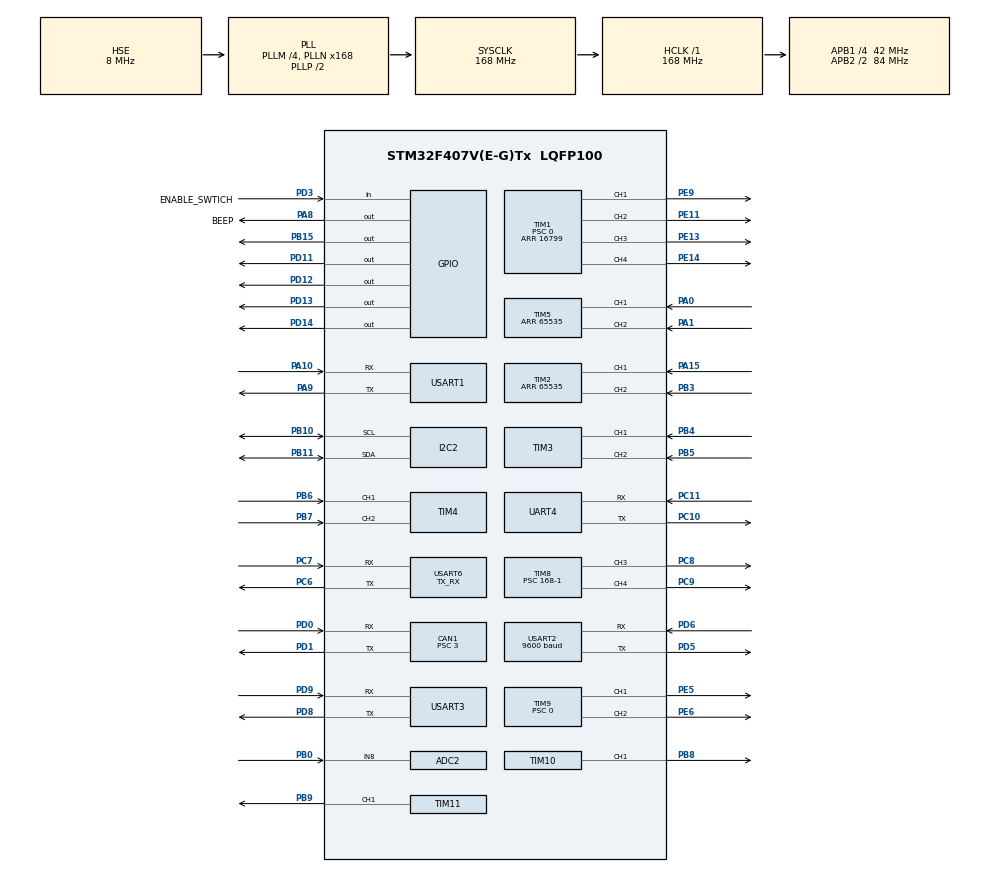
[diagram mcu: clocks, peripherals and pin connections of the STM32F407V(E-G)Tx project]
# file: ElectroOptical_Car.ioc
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ADC2.Channel-0\#ChannelRegularConversion=ADC_CHANNEL_8
ADC2.ContinuousConvMode=ENABLE
ADC2.NbrOfConversionFlag=1
ADC2.Rank-0\#ChannelRegularConversion=1
ADC2.SamplingTime-0\#ChannelRegularConversion=ADC_SAMPLETIME_3CYCLES
ADC2.ScanConvMode=ENABLE
CAN1.ABOM=ENABLE
CAN1.AWUM=ENABLE
CAN1.BS1=CAN_BS1_6TQ
CAN1.BS2=CAN_BS2_7TQ
CAN1.CalculateBaudRate=1000000
CAN1.CalculateTimeBit=1000
CAN1.CalculateTimeQuantum=71.42857142857143
CAN1.Prescaler=3
Dma.ADC2.6.Direction=DMA_PERIPH_TO_MEMORY
Dma.ADC2.6.FIFOMode=DMA_FIFOMODE_DISABLE
Dma.ADC2.6.Instance=DMA2_Stream3
Dma.ADC2.6.MemDataAlignment=DMA_MDATAALIGN_HALFWORD
Dma.ADC2.6.MemInc=DMA_MINC_ENABLE
Dma.ADC2.6.Mode=DMA_CIRCULAR
Dma.ADC2.6.PeriphDataAlignment=DMA_PDATAALIGN_HALFWORD
Dma.ADC2.6.PeriphInc=DMA_PINC_DISABLE
Dma.ADC2.6.Priority=DMA_PRIORITY_LOW
Dma.Request0=USART3_RX
Dma.Request1=USART1_RX
Dma.Request2=USART6_RX
Dma.Request3=USART3_TX
Dma.Request4=UART4_RX
Dma.Request5=UART4_TX
Dma.Request6=ADC2
Dma.UART4_RX.4.Direction=DMA_PERIPH_TO_MEMORY
Dma.UART4_RX.4.FIFOMode=DMA_FIFOMODE_ENABLE
Dma.UART4_RX.4.FIFOThreshold=DMA_FIFO_THRESHOLD_FULL
Dma.UART4_RX.4.Instance=DMA1_Stream2
Dma.UART4_RX.4.MemBurst=DMA_MBURST_SINGLE
Dma.UART4_RX.4.MemDataAlignment=DMA_MDATAALIGN_BYTE
Dma.UART4_RX.4.MemInc=DMA_MINC_ENABLE
Dma.UART4_RX.4.Mode=DMA_NORMAL
Dma.UART4_RX.4.PeriphBurst=DMA_PBURST_SINGLE
Dma.UART4_RX.4.PeriphDataAlignment=DMA_PDATAALIGN_BYTE
Dma.UART4_RX.4.PeriphInc=DMA_PINC_DISABLE
Dma.UART4_RX.4.Priority=DMA_PRIORITY_LOW
Dma.UART4_TX.5.Direction=DMA_MEMORY_TO_PERIPH
Dma.UART4_TX.5.FIFOMode=DMA_FIFOMODE_ENABLE
Dma.UART4_TX.5.FIFOThreshold=DMA_FIFO_THRESHOLD_FULL
Dma.UART4_TX.5.Instance=DMA1_Stream4
Dma.UART4_TX.5.MemBurst=DMA_MBURST_SINGLE
Dma.UART4_TX.5.MemDataAlignment=DMA_MDATAALIGN_BYTE
Dma.UART4_TX.5.MemInc=DMA_MINC_ENABLE
Dma.UART4_TX.5.Mode=DMA_NORMAL
Dma.UART4_TX.5.PeriphBurst=DMA_PBURST_SINGLE
Dma.UART4_TX.5.PeriphDataAlignment=DMA_PDATAALIGN_BYTE
Dma.UART4_TX.5.PeriphInc=DMA_PINC_DISABLE
Dma.UART4_TX.5.Priority=DMA_PRIORITY_LOW
Dma.USART1_RX.1.Direction=DMA_PERIPH_TO_MEMORY
Dma.USART1_RX.1.FIFOMode=DMA_FIFOMODE_DISABLE
Dma.USART1_RX.1.Instance=DMA2_Stream2
Dma.USART1_RX.1.MemDataAlignment=DMA_MDATAALIGN_BYTE
Dma.USART1_RX.1.MemInc=DMA_MINC_ENABLE
Dma.USART1_RX.1.Mode=DMA_NORMAL
Dma.USART1_RX.1.PeriphDataAlignment=DMA_PDATAALIGN_BYTE
Dma.USART1_RX.1.PeriphInc=DMA_PINC_DISABLE
Dma.USART1_RX.1.Priority=DMA_PRIORITY_LOW
Dma.USART3_RX.0.Direction=DMA_PERIPH_TO_MEMORY
Dma.USART3_RX.0.FIFOMode=DMA_FIFOMODE_DISABLE
Dma.USART3_RX.0.Instance=DMA1_Stream1
Dma.USART3_RX.0.MemDataAlignment=DMA_MDATAALIGN_BYTE
Dma.USART3_RX.0.MemInc=DMA_MINC_ENABLE
Dma.USART3_RX.0.Mode=DMA_NORMAL
Dma.USART3_RX.0.PeriphDataAlignment=DMA_PDATAALIGN_BYTE
Dma.USART3_RX.0.PeriphInc=DMA_PINC_DISABLE
Dma.USART3_RX.0.Priority=DMA_PRIORITY_VERY_HIGH
Dma.USART3_TX.3.Direction=DMA_MEMORY_TO_PERIPH
Dma.USART3_TX.3.FIFOMode=DMA_FIFOMODE_ENABLE
Dma.USART3_TX.3.FIFOThreshold=DMA_FIFO_THRESHOLD_FULL
Dma.USART3_TX.3.Instance=DMA1_Stream3
Dma.USART3_TX.3.MemBurst=DMA_MBURST_SINGLE
Dma.USART3_TX.3.MemDataAlignment=DMA_MDATAALIGN_BYTE
Dma.USART3_TX.3.MemInc=DMA_MINC_ENABLE
Dma.USART3_TX.3.Mode=DMA_NORMAL
Dma.USART3_TX.3.PeriphBurst=DMA_PBURST_SINGLE
Dma.USART3_TX.3.PeriphDataAlignment=DMA_PDATAALIGN_BYTE
Dma.USART3_TX.3.PeriphInc=DMA_PINC_DISABLE
Dma.USART3_TX.3.Priority=DMA_PRIORITY_LOW
Dma.USART6_RX.2.Direction=DMA_PERIPH_TO_MEMORY
Dma.USART6_RX.2.FIFOMode=DMA_FIFOMODE_ENABLE
Dma.USART6_RX.2.FIFOThreshold=DMA_FIFO_THRESHOLD_FULL
Dma.USART6_RX.2.Instance=DMA2_Stream1
Dma.USART6_RX.2.MemBurst=DMA_MBURST_SINGLE
Dma.USART6_RX.2.MemDataAlignment=DMA_MDATAALIGN_BYTE
Dma.USART6_RX.2.MemInc=DMA_MINC_ENABLE
Dma.USART6_RX.2.Mode=DMA_NORMAL
Dma.USART6_RX.2.PeriphBurst=DMA_PBURST_SINGLE
Dma.USART6_RX.2.PeriphDataAlignment=DMA_PDATAALIGN_BYTE
Dma.USART6_RX.2.PeriphInc=DMA_PINC_DISABLE
Dma.USART6_RX.2.Priority=DMA_PRIORITY_VERY_HIGH
Mcu.Family=STM32F4
Mcu.Name=STM32F407V(E-G)Tx
Mcu.Package=LQFP100
NVIC.CAN1_RX0_IRQn=true\:0\:0\:false\:false\:true\:true\:true\:true
NVIC.CAN1_RX1_IRQn=true\:0\:0\:false\:false\:true\:true\:true\:true
NVIC.DMA1_Stream1_IRQn=true\:0\:0\:false\:false\:true\:false\:true\:true
NVIC.DMA1_Stream2_IRQn=true\:0\:0\:false\:false\:true\:false\:true\:true
NVIC.DMA1_Stream3_IRQn=true\:0\:0\:false\:false\:true\:false\:true\:true
NVIC.DMA1_Stream4_IRQn=true\:0\:0\:false\:false\:true\:false\:true\:true
NVIC.DMA2_Stream1_IRQn=true\:0\:0\:false\:false\:true\:false\:true\:true
NVIC.DMA2_Stream2_IRQn=true\:0\:0\:false\:false\:true\:false\:true\:true
NVIC.DMA2_Stream3_IRQn=true\:0\:0\:false\:false\:true\:false\:true\:true
NVIC.PriorityGroup=NVIC_PRIORITYGROUP_2
NVIC.TIM6_DAC_IRQn=true\:0\:0\:false\:false\:true\:true\:true\:true
NVIC.UART4_IRQn=true\:0\:0\:false\:false\:true\:true\:true\:true
NVIC.USART1_IRQn=true\:0\:0\:false\:false\:true\:true\:true\:true
NVIC.USART2_IRQn=true\:0\:0\:false\:false\:true\:true\:true\:true
NVIC.USART3_IRQn=true\:0\:0\:false\:false\:true\:true\:true\:true
NVIC.USART6_IRQn=true\:0\:0\:false\:false\:true\:true\:true\:true
PA0-WKUP.Signal=S_TIM5_CH1
PA1.Signal=S_TIM5_CH2
PA10.Mode=Asynchronous
PA10.Signal=USART1_RX
PA13.Mode=Serial_Wire
PA13.Signal=SYS_JTMS-SWDIO
PA14.Mode=Serial_Wire
PA14.Signal=SYS_JTCK-SWCLK
PA15.Signal=S_TIM2_CH1_ETR
PA8.GPIO_Label=BEEP
PA8.Signal=GPIO_Output
PA9.Mode=Asynchronous
PA9.Signal=USART1_TX
PB0.Signal=ADCx_IN8
PB10.Mode=I2C
PB10.Signal=I2C2_SCL
PB11.Mode=I2C
PB11.Signal=I2C2_SDA
PB15.Signal=GPIO_Output
PB3.Signal=S_TIM2_CH2
PB4.Signal=S_TIM3_CH1
PB5.Signal=S_TIM3_CH2
PB6.Signal=S_TIM4_CH1
PB7.Signal=S_TIM4_CH2
PB8.GPIO_ModeDefaultPP=GPIO_MODE_AF_PP
PB8.GPIO_PuPd=GPIO_PULLUP
PB8.GPIO_Speed=GPIO_SPEED_FREQ_HIGH
PB8.Signal=S_TIM10_CH1
PB9.GPIO_PuPd=GPIO_PULLUP
PB9.GPIO_Speed=GPIO_SPEED_FREQ_HIGH
PB9.Signal=S_TIM11_CH1
PC10.Mode=Asynchronous
PC10.Signal=UART4_TX
PC11.Mode=Asynchronous
PC11.Signal=UART4_RX
PC6.Mode=Asynchronous
PC6.Signal=USART6_TX
PC7.Mode=Asynchronous
PC7.Signal=USART6_RX
PC8.Signal=S_TIM8_CH3
PC9.Signal=S_TIM8_CH4
PD0.Mode=CAN_Activate
PD0.Signal=CAN1_RX
PD1.Mode=CAN_Activate
PD1.Signal=CAN1_TX
PD11.PinState=GPIO_PIN_RESET
PD11.Signal=GPIO_Output
PD12.PinState=GPIO_PIN_RESET
PD12.Signal=GPIO_Output
PD13.Signal=GPIO_Output
PD14.Signal=GPIO_Output
PD3.GPIO_Label=ENABLE_SWTICH
PD3.GPIO_PuPd=GPIO_PULLUP
PD3.Signal=GPIO_Input
PD5.Mode=Asynchronous
PD5.Signal=USART2_TX
PD6.Mode=Asynchronous
PD6.Signal=USART2_RX
PD8.Mode=Asynchronous
PD8.Signal=USART3_TX
PD9.Mode=Asynchronous
PD9.Signal=USART3_RX
PE11.GPIO_PuPd=GPIO_PULLUP
PE11.GPIO_Speed=GPIO_SPEED_FREQ_HIGH
PE11.Signal=S_TIM1_CH2
PE13.GPIO_ModeDefaultPP=GPIO_MODE_AF_PP
PE13.GPIO_PuPd=GPIO_PULLUP
PE13.GPIO_Speed=GPIO_SPEED_FREQ_HIGH
PE13.Signal=S_TIM1_CH3
PE14.GPIO_PuPd=GPIO_PULLUP
PE14.GPIO_Speed=GPIO_SPEED_FREQ_HIGH
PE14.Signal=S_TIM1_CH4
PE5.GPIO_ModeDefaultPP=GPIO_MODE_AF_PP
PE5.GPIO_PuPd=GPIO_PULLUP
PE5.GPIO_Speed=GPIO_SPEED_FREQ_HIGH
PE5.Signal=S_TIM9_CH1
PE6.GPIO_PuPd=GPIO_PULLUP
PE6.GPIO_Speed=GPIO_SPEED_FREQ_HIGH
PE6.Signal=S_TIM9_CH2
PE9.GPIO_PuPd=GPIO_PULLUP
PE9.GPIO_Speed=GPIO_SPEED_FREQ_HIGH
PE9.Signal=S_TIM1_CH1
PH0-OSC_IN.Mode=HSE-External-Oscillator
PH0-OSC_IN.Signal=RCC_OSC_IN
PH1-OSC_OUT.Mode=HSE-External-Oscillator
PH1-OSC_OUT.Signal=RCC_OSC_OUT
ProjectManager.HeapSize=0x200
ProjectManager.StackSize=0x400
ProjectManager.TargetToolchain=MDK-ARM V5.32
RCC.48MHZClocksFreq_Value=84000000
RCC.AHBFreq_Value=168000000
RCC.APB1CLKDivider=RCC_HCLK_DIV4
RCC.APB1Freq_Value=42000000
RCC.APB1TimFreq_Value=84000000
RCC.APB2CLKDivider=RCC_HCLK_DIV2
RCC.APB2Freq_Value=84000000
RCC.APB2TimFreq_Value=168000000
RCC.CortexFreq_Value=168000000
RCC.HCLKFreq_Value=168000000
RCC.HSE_VALUE=8000000
RCC.HSI_VALUE=16000000
RCC.LSE_VALUE=32768
RCC.PLLM=4
RCC.PLLN=168
RCC.PLLSourceVirtual=RCC_PLLSOURCE_HSE
RCC.SYSCLKFreq_VALUE=168000000
RCC.SYSCLKSource=RCC_SYSCLKSOURCE_PLLCLK
RCC.VCOOutputFreq_Value=336000000
SH.ADCx_IN8.0=ADC2_IN8,IN8
SH.S_TIM10_CH1.0=TIM10_CH1,PWM Generation1 CH1
SH.S_TIM11_CH1.0=TIM11_CH1,PWM Generation1 CH1
SH.S_TIM1_CH1.0=TIM1_CH1,PWM Generation1 CH1
SH.S_TIM1_CH2.0=TIM1_CH2,PWM Generation2 CH2
SH.S_TIM1_CH3.0=TIM1_CH3,PWM Generation3 CH3
SH.S_TIM1_CH4.0=TIM1_CH4,PWM Generation4 CH4
SH.S_TIM2_CH1_ETR.0=TIM2_CH1,Encoder_Interface
SH.S_TIM2_CH2.0=TIM2_CH2,Encoder_Interface
SH.S_TIM3_CH1.0=TIM3_CH1,Encoder_Interface
SH.S_TIM3_CH2.0=TIM3_CH2,Encoder_Interface
SH.S_TIM4_CH1.0=TIM4_CH1,Encoder_Interface
SH.S_TIM4_CH2.0=TIM4_CH2,Encoder_Interface
SH.S_TIM5_CH1.0=TIM5_CH1,Encoder_Interface
SH.S_TIM5_CH2.0=TIM5_CH2,Encoder_Interface
SH.S_TIM8_CH3.0=TIM8_CH3,PWM Generation3 CH3
SH.S_TIM8_CH4.0=TIM8_CH4,PWM Generation4 CH4
SH.S_TIM9_CH1.0=TIM9_CH1,PWM Generation1 CH1
SH.S_TIM9_CH2.0=TIM9_CH2,PWM Generation2 CH2
STMicroelectronics.X-CUBE-ALGOBUILD.1.4.0.LibraryCcDSPOoLibraryJjDSPOoLibrary=true
TIM1.AutoReloadPreload=TIM_AUTORELOAD_PRELOAD_ENABLE
TIM1.Channel-PWM\ Generation1\ CH1=TIM_CHANNEL_1
TIM1.Channel-PWM\ Generation2\ CH2=TIM_CHANNEL_2
TIM1.Channel-PWM\ Generation3\ CH3=TIM_CHANNEL_3
TIM1.Channel-PWM\ Generation4\ CH4=TIM_CHANNEL_4
TIM1.Period=16799
TIM1.Prescaler=0
TIM10.AutoReloadPreload=TIM_AUTORELOAD_PRELOAD_ENABLE
TIM10.Channel=TIM_CHANNEL_1
TIM10.Period=16799
TIM10.Prescaler=0
TIM11.AutoReloadPreload=TIM_AUTORELOAD_PRELOAD_ENABLE
TIM11.Channel=TIM_CHANNEL_1
TIM11.Period=16799
TIM11.Prescaler=0
TIM2.EncoderMode=TIM_ENCODERMODE_TI12
TIM2.Period=65535
TIM3.EncoderMode=TIM_ENCODERMODE_TI12
TIM4.EncoderMode=TIM_ENCODERMODE_TI12
TIM5.AutoReloadPreload=TIM_AUTORELOAD_PRELOAD_DISABLE
TIM5.EncoderMode=TIM_ENCODERMODE_TI12
TIM5.Period=65535
TIM6.AutoReloadPreload=TIM_AUTORELOAD_PRELOAD_ENABLE
TIM6.Period=1000-1
TIM6.Prescaler=168-1
TIM8.AutoReloadPreload=TIM_AUTORELOAD_PRELOAD_DISABLE
TIM8.Channel-PWM\ Generation3\ CH3=TIM_CHANNEL_3
TIM8.Channel-PWM\ Generation4\ CH4=TIM_CHANNEL_4
TIM8.ClockDivision=TIM_CLOCKDIVISION_DIV2
TIM8.Period=20000-1
TIM8.Prescaler=168-1
TIM8.Pulse-PWM\ Generation3\ CH3=1500
TIM8.Pulse-PWM\ Generation4\ CH4=1500
TIM9.AutoReloadPreload=TIM_AUTORELOAD_PRELOAD_ENABLE
TIM9.Channel-PWM\ Generation1\ CH1=TIM_CHANNEL_1
TIM9.Channel-PWM\ Generation2\ CH2=TIM_CHANNEL_2
TIM9.Period=16799
TIM9.Prescaler=0
UART4.VirtualMode=Asynchronous
USART1.VirtualMode=VM_ASYNC
USART2.BaudRate=9600
USART2.VirtualMode=VM_ASYNC
USART3.VirtualMode=VM_ASYNC
USART6.Mode=MODE_TX_RX
USART6.VirtualMode=VM_ASYNC
VP_STMicroelectronics.X-CUBE-ALGOBUILD_VS_DSPOoLibraryJjLibrary_1.4.0_1.4.0.Mode=DSPOoLibraryJjLibrary
VP_TIM10_VS_ClockSourceINT.Mode=Enable_Timer
VP_TIM11_VS_ClockSourceINT.Mode=Enable_Timer
VP_TIM1_VS_ClockSourceINT.Mode=Internal
VP_TIM6_VS_ClockSourceINT.Mode=Enable_Timer
VP_TIM8_VS_ClockSourceINT.Mode=Internal
VP_TIM9_VS_ClockSourceINT.Mode=Internal
board=custom

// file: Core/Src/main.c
/* USER CODE BEGIN Header */
/**
  ******************************************************************************
  * @file           : main.c
  * @brief          : Main program body
  ******************************************************************************
  * @attention
  *
  * Copyright (c) 2025 STMicroelectronics.
  * All rights reserved.
  *
  * This software is licensed under terms that can be found in the LICENSE file
  * in the root directory of this software component.
  * If no LICENSE file comes with this software, it is provided AS-IS.
  *
  ******************************************************************************
  */
/* USER CODE END Header */
#include "main.h"
#include "adc.h"
#include "can.h"
#include "dma.h"
#include "i2c.h"
#include "tim.h"
#include "usart.h"
#include "gpio.h"

/* USER CODE BEGIN Includes */
#include "task.h"
/* USER CODE END Includes */

void SystemClock_Config(void);

int main(void)
{

  /* MCU Configuration--------------------------------------------------------*/

  /* Reset of all peripherals, Initializes the Flash interface and the Systick. */
  HAL_Init();

  /* Configure the system clock */
  SystemClock_Config();

  /* Initialize all configured peripherals */
  MX_GPIO_Init();
  MX_DMA_Init();
  MX_TIM1_Init();
  MX_TIM2_Init();
  MX_TIM3_Init();
  MX_TIM4_Init();
  MX_TIM5_Init();
  MX_CAN1_Init();
  MX_USART3_UART_Init();
  MX_TIM9_Init();
  MX_TIM10_Init();
  MX_TIM11_Init();
  MX_USART1_UART_Init();
  MX_TIM8_Init();
  MX_I2C2_Init();
  MX_USART6_UART_Init();
  MX_TIM6_Init();
  MX_UART4_Init();
  MX_USART2_UART_Init();
  MX_ADC2_Init();
  /* USER CODE BEGIN 2 */
  Task_Init();
  /* USER CODE END 2 */

  /* Infinite loop */
  while (1)
  {

    /* USER CODE BEGIN 3 */
		Task_Loop();
  }
  /* USER CODE END 3 */
}

void SystemClock_Config(void)
{
  RCC_OscInitTypeDef RCC_OscInitStruct = {0};
  RCC_ClkInitTypeDef RCC_ClkInitStruct = {0};

  /** Configure the main internal regulator output voltage
  */
  __HAL_RCC_PWR_CLK_ENABLE();
  __HAL_PWR_VOLTAGESCALING_CONFIG(PWR_REGULATOR_VOLTAGE_SCALE1);

  /** Initializes the RCC Oscillators according to the specified parameters
  * in the RCC_OscInitTypeDef structure.
  */
  RCC_OscInitStruct.OscillatorType = RCC_OSCILLATORTYPE_HSE;
  RCC_OscInitStruct.HSEState = RCC_HSE_ON;
  RCC_OscInitStruct.PLL.PLLState = RCC_PLL_ON;
  RCC_OscInitStruct.PLL.PLLSource = RCC_PLLSOURCE_HSE;
  RCC_OscInitStruct.PLL.PLLM = 4;
  RCC_OscInitStruct.PLL.PLLN = 168;
  RCC_OscInitStruct.PLL.PLLP = RCC_PLLP_DIV2;
  RCC_OscInitStruct.PLL.PLLQ = 4;
  if (HAL_RCC_OscConfig(&RCC_OscInitStruct) != HAL_OK)
  {
    Error_Handler();
  }

  /** Initializes the CPU, AHB and APB buses clocks
  */
  RCC_ClkInitStruct.ClockType = RCC_CLOCKTYPE_HCLK|RCC_CLOCKTYPE_SYSCLK
                              |RCC_CLOCKTYPE_PCLK1|RCC_CLOCKTYPE_PCLK2;
  RCC_ClkInitStruct.SYSCLKSource = RCC_SYSCLKSOURCE_PLLCLK;
  RCC_ClkInitStruct.AHBCLKDivider = RCC_SYSCLK_DIV1;
  RCC_ClkInitStruct.APB1CLKDivider = RCC_HCLK_DIV4;
  RCC_ClkInitStruct.APB2CLKDivider = RCC_HCLK_DIV2;

  if (HAL_RCC_ClockConfig(&RCC_ClkInitStruct, FLASH_LATENCY_5) != HAL_OK)
  {
    Error_Handler();
  }
}

void Error_Handler(void)
{
  __disable_irq();
  while (1)
  {
  }
}
